# dsPIC33FJ64GS606 register map
Vendor: Microchip; Series: dsPIC33FJ64GS; File version: 1.4.228
Generated from Microchip MPLAB X device pack files p33FJ64GS606.gld and p33FJ64GS606.h
Registers are 16-bit, read-write, no defined reset value unless marked. A register's access mark holds for its fields unless they carry their own. Offsets are from the block's base; lines under a group give offsets from that group; [hi:lo] are bit positions; {n}, {i} and the like mark numbered series; 'fields as' and 'values as' point back to an identical list; <NAME> marks a mode.

## Memory map
0x00000020 CPU_CORE size 0x34 — CPU_CORE peripheral registers
0x00000060 GPIO_CN size 0xC — GPIO_CN peripheral registers
0x00000080 INTERRUPT size 0x62 — INTERRUPT peripheral registers
0x00000100 TIMER1 size 0x6 — TIMER1 peripheral registers
0x00000106 TIMER2 size 0xC — TIMER2 peripheral registers
0x00000108 TIMER3 size 0xC — TIMER3 peripheral registers
0x00000114 TIMER4 size 0xC — TIMER4 peripheral registers
0x00000116 TIMER5 size 0xC — TIMER5 peripheral registers
0x00000140 IC1 size 0x4 — IC1 peripheral registers
0x00000144 IC2 size 0x4 — IC2 peripheral registers
0x00000148 IC3 size 0x4 — IC3 peripheral registers
0x0000014C IC4 size 0x4 — IC4 peripheral registers
0x00000180 OC1 size 0x6 — OC1 peripheral registers
0x00000186 OC2 size 0x6 — OC2 peripheral registers
0x0000018C OC3 size 0x6 — OC3 peripheral registers
0x00000192 OC4 size 0x6 — OC4 peripheral registers
0x000001E0 QEI1 size 0x8 — QEI1 peripheral registers
0x000001F0 QEI2 size 0x8 — QEI2 peripheral registers
0x00000200 I2C1 size 0xE — I2C1 peripheral registers
0x00000210 I2C2 size 0xE — I2C2 peripheral registers
0x00000220 UART1 size 0xA — UART1 peripheral registers
0x00000230 UART2 size 0xA — UART2 peripheral registers
0x00000240 SPI1 size 0xA — SPI1 peripheral registers
0x00000260 SPI2 size 0xA — SPI2 peripheral registers
0x000002C8 GPIOB size 0x6 — GPIOB peripheral registers
0x000002D0 GPIOC size 0x6 — GPIOC peripheral registers
0x000002D8 GPIOD size 0x8 — GPIOD peripheral registers
0x000002E0 GPIOE size 0x8 — GPIOE peripheral registers
0x000002E8 GPIOF size 0x8 — GPIOF peripheral registers
0x000002F0 GPIOG size 0x8 — GPIOG peripheral registers
0x00000300 ADC size 0x74 — ADC peripheral registers
0x00000380 DMA0 size 0xC — DMA0 peripheral registers
0x0000038C DMA1 size 0xC — DMA1 peripheral registers
0x00000398 DMA2 size 0xC — DMA2 peripheral registers
0x000003A4 DMA3 size 0xC — DMA3 peripheral registers
0x000003E0 DMA size 0x6 — DMA peripheral registers
0x00000400 PWM_MASTER size 0x1C — PWM_MASTER peripheral registers
0x00000420 PWM1 size 0x20 — PWM1 peripheral registers
0x00000440 PWM2 size 0x20 — PWM2 peripheral registers
0x00000460 PWM3 size 0x20 — PWM3 peripheral registers
0x00000480 PWM4 size 0x20 — PWM4 peripheral registers
0x000004A0 PWM5 size 0x20 — PWM5 peripheral registers
0x000004C0 PWM6 size 0x20 — PWM6 peripheral registers
0x00000540 CMP1 size 0x4 — CMP1 peripheral registers
0x00000544 CMP2 size 0x4 — CMP2 peripheral registers
0x00000548 CMP3 size 0x4 — CMP3 peripheral registers
0x0000054C CMP4 size 0x4 — CMP4 peripheral registers
0x00000600 CAN1 size 0x80 — CAN1 peripheral registers
0x00000740 CLOCK size 0x12 — CLOCK peripheral registers
0x00000760 NVM size 0x8 — NVM peripheral registers
0x00000770 PMD size 0xE — PMD peripheral registers
0x00F80000 CONFIG size 0x12 — Configuration words stored in program space

## CPU_CORE — CPU_CORE peripheral registers
Base 0x00000020
0x00 SPLIM
0x02 ACCAL
0x04 ACCAH
0x06 ACCAU
0x08 ACCBL
0x0A ACCBH
0x0C ACCBU
0x0E PCL
0x10 PCH
0x12 TBLPAG
0x14 PSVPAG
0x16 RCOUNT
0x18 DCOUNT
0x1A DOSTARTL
0x1C DOSTARTH
0x1E DOENDL
0x20 DOENDH
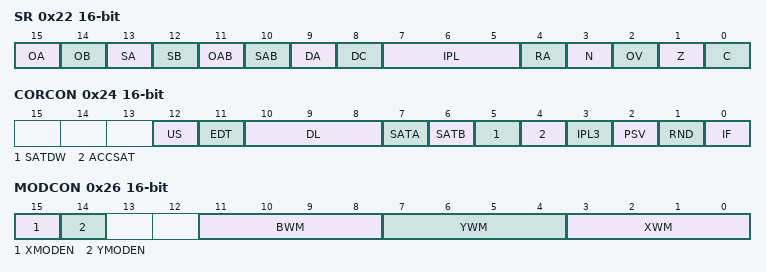
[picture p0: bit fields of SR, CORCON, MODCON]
0x22 SR
  [15] OA — Accumulator A overflow status bit
  [14] OB — Accumulator B overflow status bit
  [13] SA — Accumulator A saturation sticky status bit
  [12] SB — Accumulator B saturation sticky status bit
  [11] OAB — Combined accumulator overflow status bit
  [10] SAB — Combined accumulator saturation sticky status bit
  [9] DA — DO loop active bit
  [8] DC — MCU ALU half carry/borrow bit
  [7:5] IPL — CPU interrupt priority level status bits
  [4] RA — REPEAT loop active bit
  [3] N — MCU ALU negative bit
  [2] OV — MCU ALU overflow bit
  [1] Z — MCU ALU zero bit
  [0] C — MCU ALU carry/borrow bit
0x24 CORCON
  [12] US — DSP multiply unsigned/signed control bit
  [11] EDT — Early DO loop termination control bit
  [10:8] DL — DO loop nesting level status bits
  [7] SATA — Accumulator A saturation enable bit
  [6] SATB — Accumulator B saturation enable bit
  [5] SATDW — Data space write from DSP engine saturation enable bit
  [4] ACCSAT — Accumulator saturation mode select bit
  [3] IPL3 — CPU interrupt priority level status bit 3
  [2] PSV — Program space visibility in data space enable bit
  [1] RND — Rounding mode select bit
  [0] IF — Integer or fractional multiplier mode select bit
0x26 MODCON
  [15] XMODEN — MODCON field XMODEN
  [14] YMODEN — MODCON field YMODEN
  [11:8] BWM — MODCON field BWM
  [7:4] YWM — MODCON field YWM
  [3:0] XWM — MODCON field XWM
0x28 XMODSRT
0x2A XMODEND
0x2C YMODSRT
0x2E YMODEND
0x30 XBREV
0x32 DISICNT
